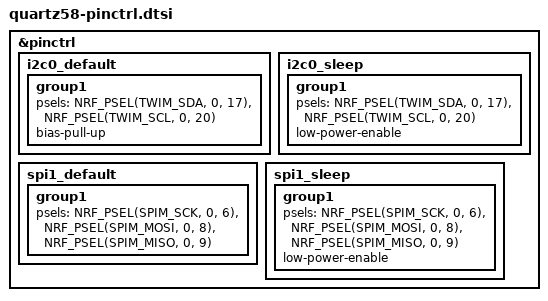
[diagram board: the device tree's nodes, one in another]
/*
 * Copyright (c) 2020 Pete Johanson
 *
 * SPDX-License-Identifier: MIT
 */

#include <dt-bindings/pinctrl/nrf-pinctrl.h>

&pinctrl {
    /* I2C configuration for OLED display */
    i2c0_default: i2c0_default {
        group1 {
            psels = <NRF_PSEL(TWIM_SDA, 0, 17)>,
                    <NRF_PSEL(TWIM_SCL, 0, 20)>;
            bias-pull-up;
        };
    };

    i2c0_sleep: i2c0_sleep {
        group1 {
            psels = <NRF_PSEL(TWIM_SDA, 0, 17)>,
                    <NRF_PSEL(TWIM_SCL, 0, 20)>;
            low-power-enable;
        };
    };

    /* SPI configuration for Nice View display */
    spi1_default: spi1_default {
        group1 {
            psels = <NRF_PSEL(SPIM_SCK, 0, 6)>,
                    <NRF_PSEL(SPIM_MOSI, 0, 8)>,
                    <NRF_PSEL(SPIM_MISO, 0, 9)>;
        };
    };

    spi1_sleep: spi1_sleep {
        group1 {
            psels = <NRF_PSEL(SPIM_SCK, 0, 6)>,
                    <NRF_PSEL(SPIM_MOSI, 0, 8)>,
                    <NRF_PSEL(SPIM_MISO, 0, 9)>;
            low-power-enable;
        };
    };

    /*
    spi3_default: spi3_default {
        group1 {
            psels = <NRF_PSEL(SPIM_MOSI, 0, 6)>;
        };
    };

    spi3_sleep: spi3_sleep {
        group1 {
            psels = <NRF_PSEL(SPIM_MOSI, 0, 6)>;
            low-power-enable;
        };
    };
    */
};
